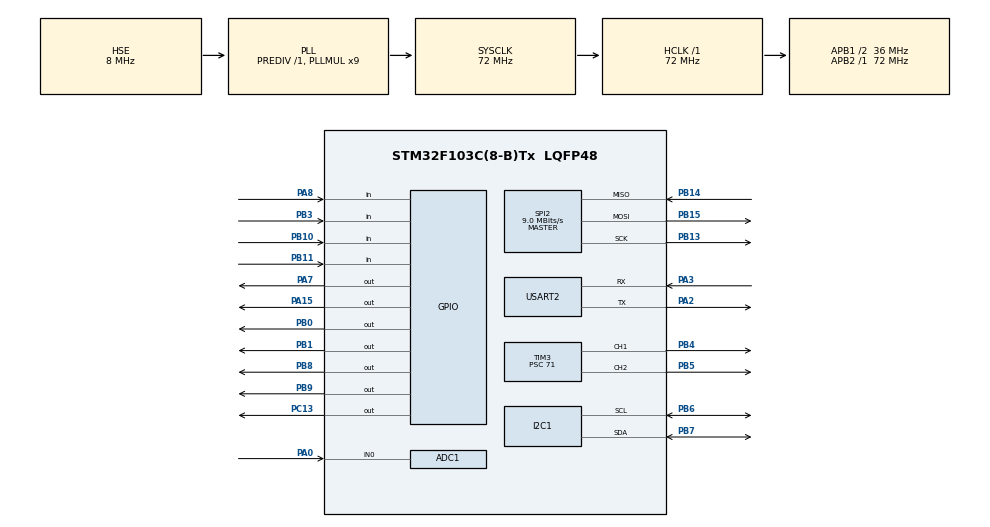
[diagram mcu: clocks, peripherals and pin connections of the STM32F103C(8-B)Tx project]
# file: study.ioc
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ADC1.Channel-0\#ChannelRegularConversion=ADC_CHANNEL_0
ADC1.ContinuousConvMode=ENABLE
ADC1.NbrOfConversionFlag=1
ADC1.Rank-0\#ChannelRegularConversion=1
ADC1.SamplingTime-0\#ChannelRegularConversion=ADC_SAMPLETIME_1CYCLE_5
ADC1.master=1
Mcu.Family=STM32F1
Mcu.Name=STM32F103C(8-B)Tx
Mcu.Package=LQFP48
NVIC.PriorityGroup=NVIC_PRIORITYGROUP_4
NVIC.USART2_IRQn=true\:0\:0\:false\:false\:true\:true\:true\:true
PA0-WKUP.Signal=ADCx_IN0
PA13.Mode=Serial_Wire
PA13.Signal=SYS_JTMS-SWDIO
PA14.Mode=Serial_Wire
PA14.Signal=SYS_JTCK-SWCLK
PA15.GPIO_PuPd=GPIO_PULLDOWN
PA15.Signal=GPIO_Output
PA2.Mode=Asynchronous
PA2.Signal=USART2_TX
PA3.Mode=Asynchronous
PA3.Signal=USART2_RX
PA7.Signal=GPIO_Output
PA8.GPIO_PuPd=GPIO_PULLUP
PA8.Signal=GPIO_Input
PB0.Signal=GPIO_Output
PB1.Signal=GPIO_Output
PB10.Signal=GPIO_Input
PB11.GPIO_PuPd=GPIO_PULLUP
PB11.Signal=GPIO_Input
PB13.Mode=Full_Duplex_Master
PB13.Signal=SPI2_SCK
PB14.Mode=Full_Duplex_Master
PB14.Signal=SPI2_MISO
PB15.Mode=Full_Duplex_Master
PB15.Signal=SPI2_MOSI
PB3.GPIO_PuPd=GPIO_PULLUP
PB3.Signal=GPIO_Input
PB4.Signal=S_TIM3_CH1
PB5.Signal=S_TIM3_CH2
PB6.Mode=I2C
PB6.Signal=I2C1_SCL
PB7.Mode=I2C
PB7.Signal=I2C1_SDA
PB8.GPIO_ModeDefaultOutputPP=GPIO_MODE_OUTPUT_OD
PB8.GPIO_PuPd=GPIO_PULLUP
PB8.Signal=GPIO_Output
PB9.GPIO_ModeDefaultOutputPP=GPIO_MODE_OUTPUT_OD
PB9.GPIO_PuPd=GPIO_PULLUP
PB9.Signal=GPIO_Output
PC13-TAMPER-RTC.Signal=GPIO_Output
PD0-OSC_IN.Mode=HSE-External-Oscillator
PD0-OSC_IN.Signal=RCC_OSC_IN
PD1-OSC_OUT.Mode=HSE-External-Oscillator
PD1-OSC_OUT.Signal=RCC_OSC_OUT
ProjectManager.HeapSize=0x200
ProjectManager.StackSize=0x400
ProjectManager.TargetToolchain=MDK-ARM V5.32
RCC.ADCPresc=RCC_ADCPCLK2_DIV6
RCC.AHBFreq_Value=72000000
RCC.APB1CLKDivider=RCC_HCLK_DIV2
RCC.APB1Freq_Value=36000000
RCC.APB1TimFreq_Value=72000000
RCC.APB2Freq_Value=72000000
RCC.APB2TimFreq_Value=72000000
RCC.HCLKFreq_Value=72000000
RCC.PLLMUL=RCC_PLL_MUL9
RCC.PLLSourceVirtual=RCC_PLLSOURCE_HSE
RCC.SYSCLKFreq_VALUE=72000000
RCC.SYSCLKSource=RCC_SYSCLKSOURCE_PLLCLK
RCC.USBFreq_Value=72000000
SH.ADCx_IN0.0=ADC1_IN0,IN0
SH.S_TIM3_CH1.0=TIM3_CH1,PWM Generation1 CH1
SH.S_TIM3_CH2.0=TIM3_CH2,PWM Generation2 CH2
SPI2.BaudRatePrescaler=SPI_BAUDRATEPRESCALER_4
SPI2.CalculateBaudRate=9.0 MBits/s
SPI2.Direction=SPI_DIRECTION_2LINES
SPI2.Mode=SPI_MODE_MASTER
SPI2.VirtualType=VM_MASTER
TIM3.AutoReloadPreload=TIM_AUTORELOAD_PRELOAD_ENABLE
TIM3.Channel-PWM\ Generation1\ CH1=TIM_CHANNEL_1
TIM3.Channel-PWM\ Generation2\ CH2=TIM_CHANNEL_2
TIM3.Period=19999
TIM3.Prescaler=71
USART2.VirtualMode=VM_ASYNC
VP_TIM3_VS_ClockSourceINT.Mode=Internal
board=custom

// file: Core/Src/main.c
/* USER CODE BEGIN Header */
/**
  ******************************************************************************
  * @file           : main.c
  * @brief          : Main program body
  ******************************************************************************
  * @attention
  *
  * Copyright (c) 2026 STMicroelectronics.
  * All rights reserved.
  *
  * This software is licensed under terms that can be found in the LICENSE file
  * in the root directory of this software component.
  * If no LICENSE file comes with this software, it is provided AS-IS.
  *
  ******************************************************************************
  */
/* USER CODE END Header */
#include "main.h"
#include "adc.h"
#include "i2c.h"
#include "spi.h"
#include "tim.h"
#include "usart.h"
#include "gpio.h"

/* USER CODE BEGIN Includes */
#include "OLED.h"
#include "function.h"
#include "message.h"
#include "aht30.h"
/* USER CODE END Includes */

void SystemClock_Config(void);

int main(void)
{

  /* MCU Configuration--------------------------------------------------------*/

  /* Reset of all peripherals, Initializes the Flash interface and the Systick. */
  HAL_Init();

  /* Configure the system clock */
  SystemClock_Config();

  /* Initialize all configured peripherals */
  MX_GPIO_Init();
  MX_TIM3_Init();
  MX_USART2_UART_Init();
  MX_I2C1_Init();
  MX_SPI2_Init();
  MX_ADC1_Init();
  /* USER CODE BEGIN 2 */
  LED_Init();
  Buzzer_Init();
  Key_Init();
  OLED_Init();
  OLED_ShowString(1, 1, "Hello");
  OLED_ShowString(2, 1, "Fish");
  Servo_Init();                 /* 启动舵机 PWM，初始转到 0° */
  Pot_Init();                   /* 启动 ADC1 连续转换（PA0 滑动变阻器） */
  /* USER CODE END 2 */

  /* Infinite loop */
  while (1)
  {

    /* USER CODE BEGIN 3 */
    Function_Menu_Handle();     /* 菜单系统：模式选择 / 基础外设 / 舵机控制 */
  }
  /* USER CODE END 3 */
}

void SystemClock_Config(void)
{
  RCC_OscInitTypeDef RCC_OscInitStruct = {0};
  RCC_ClkInitTypeDef RCC_ClkInitStruct = {0};
  RCC_PeriphCLKInitTypeDef PeriphClkInit = {0};

  /** Initializes the RCC Oscillators according to the specified parameters
  * in the RCC_OscInitTypeDef structure.
  */
  RCC_OscInitStruct.OscillatorType = RCC_OSCILLATORTYPE_HSE;
  RCC_OscInitStruct.HSEState = RCC_HSE_ON;
  RCC_OscInitStruct.HSEPredivValue = RCC_HSE_PREDIV_DIV1;
  RCC_OscInitStruct.HSIState = RCC_HSI_ON;
  RCC_OscInitStruct.PLL.PLLState = RCC_PLL_ON;
  RCC_OscInitStruct.PLL.PLLSource = RCC_PLLSOURCE_HSE;
  RCC_OscInitStruct.PLL.PLLMUL = RCC_PLL_MUL9;
  if (HAL_RCC_OscConfig(&RCC_OscInitStruct) != HAL_OK)
  {
    Error_Handler();
  }

  /** Initializes the CPU, AHB and APB buses clocks
  */
  RCC_ClkInitStruct.ClockType = RCC_CLOCKTYPE_HCLK|RCC_CLOCKTYPE_SYSCLK
                              |RCC_CLOCKTYPE_PCLK1|RCC_CLOCKTYPE_PCLK2;
  RCC_ClkInitStruct.SYSCLKSource = RCC_SYSCLKSOURCE_PLLCLK;
  RCC_ClkInitStruct.AHBCLKDivider = RCC_SYSCLK_DIV1;
  RCC_ClkInitStruct.APB1CLKDivider = RCC_HCLK_DIV2;
  RCC_ClkInitStruct.APB2CLKDivider = RCC_HCLK_DIV1;

  if (HAL_RCC_ClockConfig(&RCC_ClkInitStruct, FLASH_LATENCY_2) != HAL_OK)
  {
    Error_Handler();
  }
  PeriphClkInit.PeriphClockSelection = RCC_PERIPHCLK_ADC;
  PeriphClkInit.AdcClockSelection = RCC_ADCPCLK2_DIV6;
  if (HAL_RCCEx_PeriphCLKConfig(&PeriphClkInit) != HAL_OK)
  {
    Error_Handler();
  }
}

void Error_Handler(void)
{
  __disable_irq();
  while (1)
  {
  }
}
